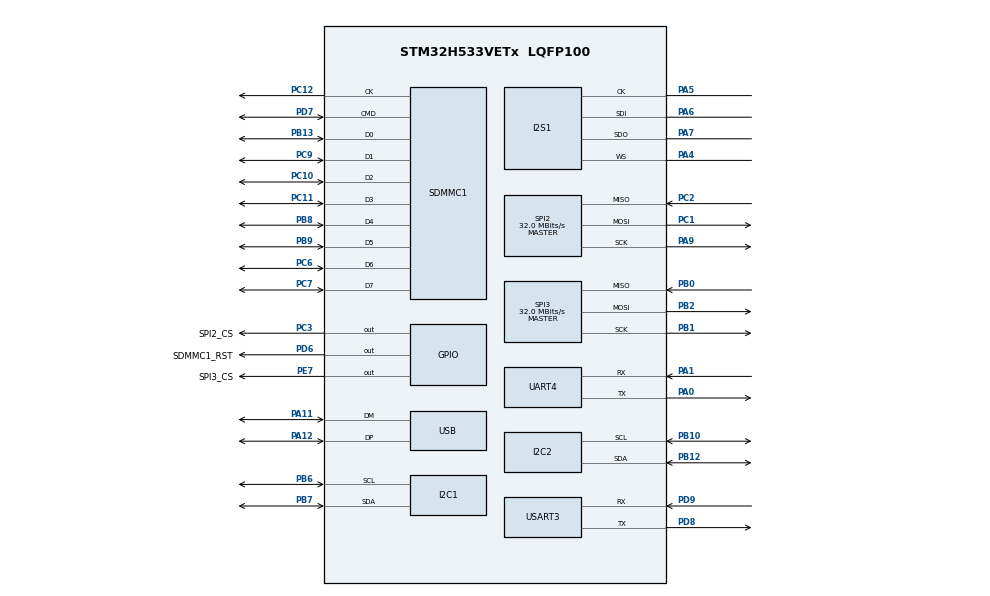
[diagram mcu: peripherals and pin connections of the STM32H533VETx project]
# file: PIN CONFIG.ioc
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BOOTPATH.BootPathName=LEGACY
BOOTPATH.UserSelectedBootPath=LEGACY
CORTEX_M33_NS.userName=CORTEX_M33
I2C1.Timing=0x00707CBB
I2C2.Timing=0x00707CBB
I2S1.ErrorAudioFreq=0.0 %
I2S1.Instance=SPI$Index
I2S1.RealAudioFreq=8.0 KHz
Mcu.Family=STM32H5
Mcu.Name=STM32H533VETx
Mcu.Package=LQFP100
NVIC.PriorityGroup=NVIC_PRIORITYGROUP_4
PA0.Mode=Asynchronous
PA0.Signal=UART4_TX
PA1.Mode=Asynchronous
PA1.Signal=UART4_RX
PA11.Mode=Host
PA11.Signal=USB_DM
PA12.Mode=Host
PA12.Signal=USB_DP
PA13(JTMS/SWDIO).Mode=Serial_Wire
PA13(JTMS/SWDIO).Signal=DEBUG_JTMS-SWDIO
PA14(JTCK/SWCLK).Mode=Serial_Wire
PA14(JTCK/SWCLK).Signal=DEBUG_JTCK-SWCLK
PA4.Mode=Full_Duplex_Master
PA4.Signal=I2S1_WS
PA5.Mode=Full_Duplex_Master
PA5.Signal=I2S1_CK
PA6.Mode=Full_Duplex_Master
PA6.Signal=I2S1_SDI
PA7.Mode=Full_Duplex_Master
PA7.Signal=I2S1_SDO
PA9.Mode=Full_Duplex_Master
PA9.Signal=SPI2_SCK
PB0.Mode=Full_Duplex_Master
PB0.Signal=SPI3_MISO
PB1.Mode=Full_Duplex_Master
PB1.Signal=SPI3_SCK
PB10.Mode=I2C
PB10.Signal=I2C2_SCL
PB12.Mode=I2C
PB12.Signal=I2C2_SDA
PB13.Mode=mmc_8_bits_Wide_bus
PB13.Signal=SDMMC1_D0
PB2.Mode=Full_Duplex_Master
PB2.Signal=SPI3_MOSI
PB6.Mode=I2C
PB6.Signal=I2C1_SCL
PB7.Mode=I2C
PB7.Signal=I2C1_SDA
PB8.Mode=mmc_8_bits_Wide_bus
PB8.Signal=SDMMC1_D4
PB9.Mode=mmc_8_bits_Wide_bus
PB9.Signal=SDMMC1_D5
PC1.Mode=Full_Duplex_Master
PC1.Signal=SPI2_MOSI
PC10.Mode=mmc_8_bits_Wide_bus
PC10.Signal=SDMMC1_D2
PC11.Mode=mmc_8_bits_Wide_bus
PC11.Signal=SDMMC1_D3
PC12.Mode=mmc_8_bits_Wide_bus
PC12.Signal=SDMMC1_CK
PC14-OSC32_IN(OSC32_IN).Mode=LSE-External-Oscillator
PC14-OSC32_IN(OSC32_IN).Signal=RCC_OSC32_IN
PC15-OSC32_OUT(OSC32_OUT).Mode=LSE-External-Oscillator
PC15-OSC32_OUT(OSC32_OUT).Signal=RCC_OSC32_OUT
PC2.Mode=Full_Duplex_Master
PC2.Signal=SPI2_MISO
PC3.GPIO_Label=SPI2_CS
PC3.Signal=GPIO_Output
PC6.Mode=mmc_8_bits_Wide_bus
PC6.Signal=SDMMC1_D6
PC7.Mode=mmc_8_bits_Wide_bus
PC7.Signal=SDMMC1_D7
PC9.Mode=mmc_8_bits_Wide_bus
PC9.Signal=SDMMC1_D1
PD6.GPIO_Label=SDMMC1_RST
PD6.Signal=GPIO_Output
PD7.Mode=mmc_8_bits_Wide_bus
PD7.Signal=SDMMC1_CMD
PD8.Mode=Asynchronous
PD8.Signal=USART3_TX
PD9.Mode=Asynchronous
PD9.Signal=USART3_RX
PE7.GPIO_Label=SPI3_CS
PE7.Signal=GPIO_Output
PH0-OSC_IN(PH0).Mode=HSE-External-Oscillator
PH0-OSC_IN(PH0).Signal=RCC_OSC_IN
PH1-OSC_OUT(PH1).Mode=HSE-External-Oscillator
PH1-OSC_OUT(PH1).Signal=RCC_OSC_OUT
ProjectManager.HeapSize=0x200
ProjectManager.StackSize=0x400
ProjectManager.TargetToolchain=STM32CubeIDE
RCC.ADCFreq_Value=32000000
RCC.AHBFreq_Value=32000000
RCC.APB1Freq_Value=32000000
RCC.APB1TimFreq_Value=32000000
RCC.APB2Freq_Value=32000000
RCC.APB2TimFreq_Value=32000000
RCC.APB3Freq_Value=32000000
RCC.CSI_VALUE=4000000
RCC.CortexFreq_Value=32000000
RCC.EPOD_VALUE=4000000
RCC.HCLKFreq_Value=32000000
RCC.HSE_VALUE=25000000
RCC.HSI48_VALUE=48000000
RCC.HSI_VALUE=64000000
RCC.LSIRC_VALUE=32000
RCC.PLLFRACN=0
RCC.PLLN=32
RCC.SYSCLKFreq_VALUE=32000000
RCC.USBFreq_Value=48000000
RCC.VCOOutputFreq_Value=128000000
SPI2.CalculateBaudRate=32.0 MBits/s
SPI2.Direction=SPI_DIRECTION_2LINES
SPI2.Mode=SPI_MODE_MASTER
SPI2.VirtualType=VM_MASTER
SPI3.CalculateBaudRate=32.0 MBits/s
SPI3.Direction=SPI_DIRECTION_2LINES
SPI3.Mode=SPI_MODE_MASTER
SPI3.VirtualType=VM_MASTER
USART3.VirtualMode=VM_ASYNC
USART3.VirtualMode-Asynchronous=VM_ASYNC
USB.VirtualMode=Host_Only
VP_BOOTPATH_VS_BOOTPATH.Mode=BP_Activate
VP_CORTEX_M33_NS_VS_Hclk.Mode=Hclk_Mode
VP_DCACHE1_VS_DCACHE.Mode=DCACHE_Activate
VP_FLASH_SIG_Activate_FlashIP.Mode=Activate_FlashIP
VP_ICACHE_VS_ICACHE.Mode=DefaultMode
VP_IWDG_VS_IWDG.Mode=IWDG_Activate
VP_MEMORYMAP_VS_MEMORYMAP.Mode=CurAppReg
VP_PWR_VS_DBSignals.Mode=DisableDeadBatterySignals
VP_PWR_VS_LPOM.Mode=PowerOptimisation
VP_PWR_VS_SECSignals.Mode=Security/Privilege
VP_WWDG_VS_WWDG.Mode=WWDG_Activate
board=custom

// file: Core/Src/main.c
#include "main.h"
#include "fatfs.h"
#include "lcd_driver.h"  // Include your LCD driver header
#include "cap_touch_driver.h"  // Include your capacitive touch driver header

// Global variables
char currentPath[256] = "0:/";  // Current directory path

// Function prototypes
void LCD_Init(void);
void CapacitiveTouch_Init(void);
void DisplayDirectory(const char* path);
void HandleTouchInput(void);

int main(void) {

    /* MCU Configuration--------------------------------------------------------*/

    /* Reset of all peripherals, Initializes the Flash interface and the Systick. */
    HAL_Init();

    /* Configure the system clock */
    SystemClock_Config();

    /* Initialize all configured peripherals */
    MX_GPIO_Init();
    MX_DCACHE1_Init();
    MX_FLASH_Init();
    MX_I2C1_Init();
    MX_I2C2_Init();
    MX_I2S1_Init();
    MX_IWDG_Init();
    MX_SDMMC1_MMC_Init();
    MX_SPI2_Init();
    MX_SPI3_Init();
    MX_UART4_Init();
    MX_USART3_UART_Init();
    MX_USB_HCD_Init();
    MX_WWDG_Init();
    MX_ICACHE_Init();

    /* USER CODE BEGIN 2 */
    LCD_Init();              // Initialize the LCD
    CapacitiveTouch_Init();  // Initialize capacitive touch
    DisplayDirectory(currentPath);  // Display root directory on the LCD
    /* USER CODE END 2 */

    /* Infinite loop */
    /* USER CODE BEGIN WHILE */
    while (1) {
        HandleTouchInput();  // Process user touch input for navigation
        /* USER CODE END WHILE */

    }
}

void DisplayDirectory(const char* path) {
    FATFS fs;
    FRESULT res;
    DIR dir;
    FILINFO fno;
    int yPos = 30;  // Start Y position for listing

    LCD_Clear();  // Clear the screen
    LCD_SetTextColor(LCD_COLOR_WHITE);
    LCD_SetBackColor(LCD_COLOR_BLACK);
    LCD_DisplayStringAt(0, 0, (uint8_t*)path, CENTER_MODE);  // Display current path

    res = f_opendir(&dir, path);
    if (res == FR_OK) {
        while (1) {
            res = f_readdir(&dir, &fno);
            if (res != FR_OK || fno.fname[0] == 0) break;  // Break on error or end of directory

            if (fno.fattrib & AM_DIR) {
                LCD_DisplayStringAt(10, yPos, (uint8_t*)"[DIR] ", LEFT_MODE);
                LCD_DisplayStringAt(60, yPos, (uint8_t*)fno.fname, LEFT_MODE);
            } else {
                LCD_DisplayStringAt(10, yPos, (uint8_t*)"[FILE] ", LEFT_MODE);
                LCD_DisplayStringAt(60, yPos, (uint8_t*)fno.fname, LEFT_MODE);
            }
            yPos += 20;  // Move to the next line
        }
        f_closedir(&dir);
    } else {
        LCD_DisplayStringAt(0, 30, (uint8_t*)"Failed to open directory.", CENTER_MODE);
    }
}

void HandleTouchInput(void) {
    CapTouch_StateTypeDef touchState;
    CapacitiveTouch_GetState(&touchState);

    if (touchState.touchDetected) {
        uint16_t x = touchState.touchX[0];
        uint16_t y = touchState.touchY[0];

        if (y < 30) {  // Touch near the top could represent "Go Back"
            char* lastSlash = strrchr(currentPath, '/');
            if (lastSlash && lastSlash != currentPath) {
                *lastSlash = '\0';
                DisplayDirectory(currentPath);
            }
        } else {
            int selectedItem = (y - 30) / 20;
            FATFS fs;
            FRESULT res;
            DIR dir;
            FILINFO fno;
            res = f_opendir(&dir, currentPath);
            if (res == FR_OK) {
                int index = 0;
                while (1) {
                    res = f_readdir(&dir, &fno);
                    if (res != FR_OK || fno.fname[0] == 0) break;
                    if (index == selectedItem) {
                        if (fno.fattrib & AM_DIR) {
                            strcat(currentPath, "/");
                            strcat(currentPath, fno.fname);
                            DisplayDirectory(currentPath);
                        } else {
                            LCD_DisplayStringAt(0, 250, (uint8_t*)"File selected!", CENTER_MODE);
                        }
                        break;
                    }
                    index++;
                }
                f_closedir(&dir);
            }
        }
    }
}

void LCD_Init(void) {
    LCD_InitHardware();  // Replace with your LCD hardware initialization function
    LCD_SetOrientation(LCD_ORIENTATION_PORTRAIT);
    LCD_Clear();
}

void CapacitiveTouch_Init(void) {
    CapacitiveTouch_InitHardware();  // Replace with your touch controller initialization function
}
